AUTOSAR XML (schema 4.0)
package /Chassis
  application sw component type WheelSpeedSensor
    provide port VehicleSpeed_P: provided-interface=/Chassis/VehicleSpeed_I
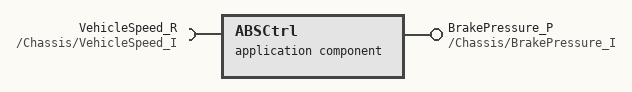
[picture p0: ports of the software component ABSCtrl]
  application sw component type ABSCtrl
    require port VehicleSpeed_R: required-interface=/Chassis/VehicleSpeed_I
    provide port BrakePressure_P: provided-interface=/Chassis/BrakePressure_I
  application sw component type BrakeActuator
    require port BrakePressure_R: required-interface=/Chassis/BrakePressure_I
